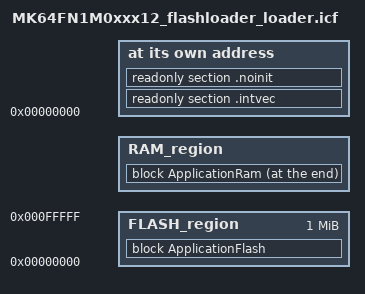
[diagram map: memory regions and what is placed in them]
/*
** ###################################################################
**     Processors:          MK64FN1M0CAJ12
**                          MK64FN1M0VDC12
**                          MK64FN1M0VLL12
**                          MK64FN1M0VLQ12
**                          MK64FN1M0VMD12
**
**     Compiler:            IAR ANSI C/C++ Compiler for ARM
**     Reference manual:    K64P144M120SF5RM, Rev.2, January 2014
**     Version:             rev. 2.9, 2016-03-21
**     Build:               b171205
**
**     Abstract:
**         Linker file for the IAR ANSI C/C++ Compiler for ARM
**
**     Copyright (c) 2015 Freescale Semiconductor, Inc.
**     Copyright 2016-2018 NXP
**     All rights reserved.
**
**     SPDX-License-Identifier: BSD-3-Clause
**
**     http:                 www.nxp.com
**     mail:                 support@nxp.com
**
** ###################################################################
*/

/*-Memory Regions-*/
define symbol __ICFEDIT_region_FLASH_start__ = 0x0;
define symbol __ICFEDIT_region_FLASH_end__   = __ICFEDIT_region_FLASH_start__ + (1024*1024) - 1 ;
define symbol __ICFEDIT_region_RAM_end__   = 0x20000000;
define symbol __ICFEDIT_region_RAM_start__ = __ICFEDIT_region_RAM_end__ - (64*1024);
/*-Specials-*/
define symbol __ICFEDIT_intvec_start__     = __ICFEDIT_region_FLASH_start__;

/*-Sizes-*/
define symbol __ICFEDIT_size_cstack__ = (1*1024);
define symbol __ICFEDIT_size_heap__   = (0*1024);

if (isdefinedsymbol(__stack_size__)) {
  define symbol __size_cstack__        = __stack_size__;
} else {
  define symbol __size_cstack__        = 0x0400;
}
if (isdefinedsymbol(__heap_size__)) {
  define symbol __size_heap__          = __heap_size__;
} else {
  define symbol __size_heap__          = 0x0;
}

define symbol __region_RAM2_start__        = 0x20000000;
define symbol __region_RAM2_end__          = __region_RAM2_start__ + ((192*1024));

define exported symbol __VECTOR_TABLE      = __ICFEDIT_region_FLASH_start__;
define exported symbol __VECTOR_RAM        = __ICFEDIT_region_RAM_start__;

define exported symbol __BOOT_STACK_ADDRESS = __region_RAM2_end__ - 8;

define memory mem with size = 4G;
define region FLASH_region = mem:[from __ICFEDIT_region_FLASH_start__ to __ICFEDIT_region_FLASH_end__];
define region RAM_region   = mem:[from __ICFEDIT_region_RAM_start__   to __ICFEDIT_region_RAM_end__] | mem:[from __region_RAM2_start__ to __region_RAM2_end__];

define block CSTACK    with alignment = 8, size = __ICFEDIT_size_cstack__   { };
define block HEAP      with alignment = 8, size = __ICFEDIT_size_heap__     { };

initialize manually { readwrite };
initialize manually { section .data};
initialize manually { section .textrw };
do not initialize  { section .noinit };

define block USBGlobal {section .bss.m_usb_bdt, section .bss.m_usb_global}; 
define block CodeRelocate { section .textrw_init };
define block CodeRelocateRam { section .textrw };
define block ApplicationFlash { readonly, block CodeRelocate };
define block ApplicationRam { readwrite, block CodeRelocateRam, block USBGlobal, block CSTACK, block HEAP };
place at address mem:__ICFEDIT_intvec_start__ { readonly section .intvec, readonly section .noinit };
place in FLASH_region { block ApplicationFlash };
place at end of RAM_region   { block ApplicationRam };
